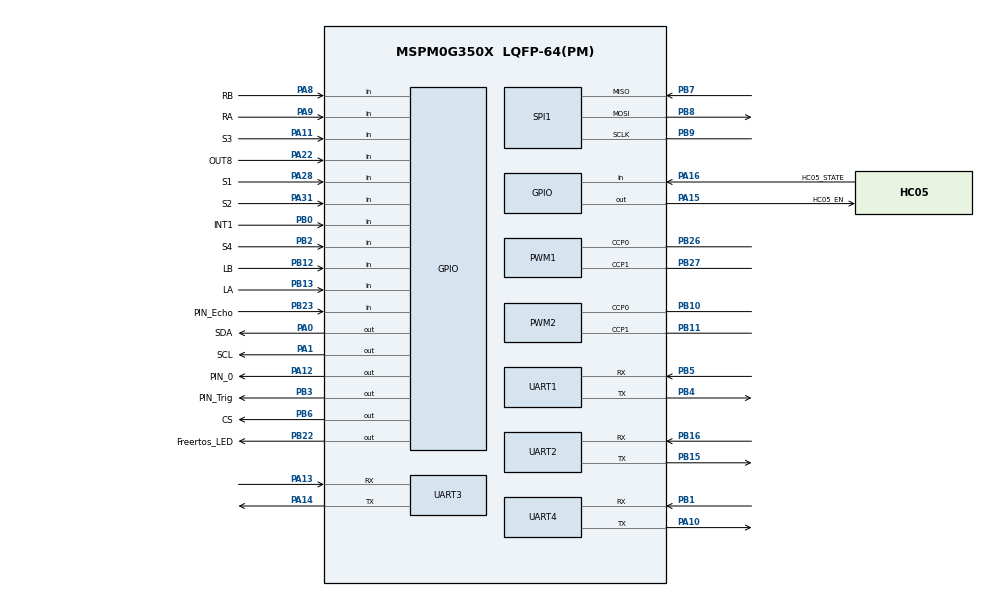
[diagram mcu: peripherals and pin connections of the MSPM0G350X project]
/**
 * @cliArgs --device "MSPM0G350X" --part "Default" --package "LQFP-64(PM)" --product "mspm0_sdk@2.10.00.04"
 * @versions {"tool":"1.27.0+4565"}
 */

/**
 * Import the modules used in this configuration.
 */
const GPIO   = scripting.addModule("/ti/driverlib/GPIO", {}, false);
const GPIO1  = GPIO.addInstance();
const GPIO2  = GPIO.addInstance();
const GPIO3  = GPIO.addInstance();
const GPIO4  = GPIO.addInstance();
const GPIO5  = GPIO.addInstance();
const GPIO6  = GPIO.addInstance();
const GPIO7  = GPIO.addInstance();
const GPIO8  = GPIO.addInstance();
const GPIO9  = GPIO.addInstance();
const GPIO10 = GPIO.addInstance();
const PWM    = scripting.addModule("/ti/driverlib/PWM", {}, false);
const PWM1   = PWM.addInstance();
const PWM2   = PWM.addInstance();
const SPI    = scripting.addModule("/ti/driverlib/SPI", {}, false);
const SPI1   = SPI.addInstance();
const SYSCTL = scripting.addModule("/ti/driverlib/SYSCTL");
const TIMER  = scripting.addModule("/ti/driverlib/TIMER", {}, false);
const TIMER1 = TIMER.addInstance();
const TIMER2 = TIMER.addInstance();
const TIMER3 = TIMER.addInstance();
const UART   = scripting.addModule("/ti/driverlib/UART", {}, false);
const UART1  = UART.addInstance();
const UART2  = UART.addInstance();
const UART3  = UART.addInstance();
const UART4  = UART.addInstance();

/**
 * Write custom configuration values to the imported modules.
 */
const divider7       = system.clockTree["PLL_PDIV"];
divider7.divideValue = 4;

const divider9       = system.clockTree["UDIV"];
divider9.divideValue = 2;

const multiplier2         = system.clockTree["PLL_QDIV"];
multiplier2.multiplyValue = 10;

const mux8       = system.clockTree["HSCLKMUX"];
mux8.inputSelect = "HSCLKMUX_SYSPLL2X";

GPIO1.$name                               = "GPIO_IMU";
GPIO1.associatedPins.create(2);
GPIO1.associatedPins[0].$name             = "CS";
GPIO1.associatedPins[0].initialValue      = "SET";
GPIO1.associatedPins[0].pin.$assign       = "PB6";
GPIO1.associatedPins[1].$name             = "INT1";
GPIO1.associatedPins[1].direction         = "INPUT";
GPIO1.associatedPins[1].polarity          = "RISE";
GPIO1.associatedPins[1].interruptPriority = "3";
GPIO1.associatedPins[1].interruptEn       = true;
GPIO1.associatedPins[1].internalResistor  = "PULL_DOWN";
GPIO1.associatedPins[1].pin.$assign       = "PB0";

const Board = scripting.addModule("/ti/driverlib/Board", {}, false);

GPIO2.$name                              = "ENCODER_A";
GPIO2.associatedPins.create(2);
GPIO2.associatedPins[0].$name            = "LA";
GPIO2.associatedPins[0].direction        = "INPUT";
GPIO2.associatedPins[0].internalResistor = "PULL_UP";
GPIO2.associatedPins[0].interruptEn      = true;
GPIO2.associatedPins[0].polarity         = "RISE";
GPIO2.associatedPins[0].pin.$assign      = "PB13";
GPIO2.associatedPins[1].$name            = "RA";
GPIO2.associatedPins[1].direction        = "INPUT";
GPIO2.associatedPins[1].internalResistor = "PULL_UP";
GPIO2.associatedPins[1].interruptEn      = true;
GPIO2.associatedPins[1].polarity         = "RISE";
GPIO2.associatedPins[1].pin.$assign      = "PA9";

GPIO3.$name                              = "ENCODER_B";
GPIO3.associatedPins.create(2);
GPIO3.associatedPins[0].$name            = "LB";
GPIO3.associatedPins[0].direction        = "INPUT";
GPIO3.associatedPins[0].internalResistor = "PULL_UP";
GPIO3.associatedPins[0].pin.$assign      = "PB12";
GPIO3.associatedPins[1].$name            = "RB";
GPIO3.associatedPins[1].direction        = "INPUT";
GPIO3.associatedPins[1].internalResistor = "PULL_UP";
GPIO3.associatedPins[1].pin.$assign      = "PA8";

GPIO4.$name                              = "GPIO_KEY";
GPIO4.associatedPins.create(4);
GPIO4.associatedPins[0].$name            = "S4";
GPIO4.associatedPins[0].direction        = "INPUT";
GPIO4.associatedPins[0].internalResistor = "PULL_UP";
GPIO4.associatedPins[0].pin.$assign      = "PB2";
GPIO4.associatedPins[1].$name            = "S3";
GPIO4.associatedPins[1].direction        = "INPUT";
GPIO4.associatedPins[1].assignedPort     = "PORTA";
GPIO4.associatedPins[1].internalResistor = "PULL_UP";
GPIO4.associatedPins[1].pin.$assign      = "PA11";
GPIO4.associatedPins[2].$name            = "S2";
GPIO4.associatedPins[2].direction        = "INPUT";
GPIO4.associatedPins[2].internalResistor = "PULL_UP";
GPIO4.associatedPins[2].pin.$assign      = "PA31";
GPIO4.associatedPins[3].$name            = "S1";
GPIO4.associatedPins[3].direction        = "INPUT";
GPIO4.associatedPins[3].internalResistor = "PULL_UP";
GPIO4.associatedPins[3].pin.$assign      = "PA28";

GPIO5.$name                              = "GPIO_Ultrasonic";
GPIO5.associatedPins.create(2);
GPIO5.associatedPins[0].$name            = "PIN_Trig";
GPIO5.associatedPins[0].pin.$assign      = "PB3";
GPIO5.associatedPins[1].$name            = "PIN_Echo";
GPIO5.associatedPins[1].direction        = "INPUT";
GPIO5.associatedPins[1].interruptEn      = true;
GPIO5.associatedPins[1].polarity         = "RISE_FALL";
GPIO5.associatedPins[1].internalResistor = "PULL_DOWN";
GPIO5.associatedPins[1].pin.$assign      = "PB23";

GPIO6.$name                          = "GPIO_GRAY";
GPIO6.associatedPins.create(8);
GPIO6.associatedPins[0].$name        = "OUT1";
GPIO6.associatedPins[0].direction    = "INPUT";
GPIO6.associatedPins[0].assignedPort = "PORTA";
GPIO6.associatedPins[0].assignedPin  = "27";
GPIO6.associatedPins[1].$name        = "OUT2";
GPIO6.associatedPins[1].direction    = "INPUT";
GPIO6.associatedPins[1].assignedPort = "PORTA";
GPIO6.associatedPins[1].assignedPin  = "26";
GPIO6.associatedPins[2].$name        = "OUT3";
GPIO6.associatedPins[2].direction    = "INPUT";
GPIO6.associatedPins[2].assignedPort = "PORTA";
GPIO6.associatedPins[2].assignedPin  = "25";
GPIO6.associatedPins[3].$name        = "OUT4";
GPIO6.associatedPins[3].direction    = "INPUT";
GPIO6.associatedPins[3].assignedPort = "PORTA";
GPIO6.associatedPins[3].assignedPin  = "24";
GPIO6.associatedPins[4].$name        = "OUT5";
GPIO6.associatedPins[4].direction    = "INPUT";
GPIO6.associatedPins[4].assignedPort = "PORTB";
GPIO6.associatedPins[4].assignedPin  = "25";
GPIO6.associatedPins[5].$name        = "OUT6";
GPIO6.associatedPins[5].direction    = "INPUT";
GPIO6.associatedPins[5].assignedPort = "PORTB";
GPIO6.associatedPins[5].assignedPin  = "24";
GPIO6.associatedPins[6].$name        = "OUT7";
GPIO6.associatedPins[6].direction    = "INPUT";
GPIO6.associatedPins[6].assignedPort = "PORTB";
GPIO6.associatedPins[6].assignedPin  = "20";
GPIO6.associatedPins[7].$name        = "OUT8";
GPIO6.associatedPins[7].direction    = "INPUT";
GPIO6.associatedPins[7].assignedPort = "PORTA";
GPIO6.associatedPins[7].assignedPin  = "22";
GPIO6.associatedPins[7].pin.$assign  = "PA22";

GPIO7.$name                          = "GPIO_OLED";
GPIO7.associatedPins.create(2);
GPIO7.associatedPins[0].$name        = "SDA";
GPIO7.associatedPins[0].initialValue = "SET";
GPIO7.associatedPins[0].assignedPort = "PORTA";
GPIO7.associatedPins[0].assignedPin  = "0";
GPIO7.associatedPins[0].ioStructure  = "OD";
GPIO7.associatedPins[0].pin.$assign  = "PA0";
GPIO7.associatedPins[1].$name        = "SCL";
GPIO7.associatedPins[1].initialValue = "SET";
GPIO7.associatedPins[1].assignedPort = "PORTA";
GPIO7.associatedPins[1].assignedPin  = "1";
GPIO7.associatedPins[1].ioStructure  = "OD";
GPIO7.associatedPins[1].pin.$assign  = "PA1";

GPIO8.$name                         = "GPIO_HC05";
GPIO8.associatedPins.create(2);
GPIO8.associatedPins[0].$name       = "HC05_EN";
GPIO8.associatedPins[0].pin.$assign = "PA15";
GPIO8.associatedPins[1].$name       = "HC05_STATE";
GPIO8.associatedPins[1].direction   = "INPUT";
GPIO8.associatedPins[1].pin.$assign = "PA16";

GPIO9.$name                         = "GPIO_LED";
GPIO9.associatedPins[0].$name       = "Freertos_LED";
GPIO9.associatedPins[0].pin.$assign = "PB22";

GPIO10.$name                          = "GPIO_BEEP";
GPIO10.associatedPins[0].$name        = "PIN_0";
GPIO10.associatedPins[0].initialValue = "SET";
GPIO10.associatedPins[0].pin.$assign  = "PA12";

PWM1.timerStartTimer                    = true;
PWM1.$name                              = "PWM_motor_L";
PWM1.timerCount                         = 7999;
PWM1.peripheral.$assign                 = "TIMG6";
PWM1.peripheral.ccp0Pin.$assign         = "PB26";
PWM1.peripheral.ccp1Pin.$assign         = "PB27";
PWM1.PWM_CHANNEL_0.$name                = "ti_driverlib_pwm_PWMTimerCC0";
PWM1.PWM_CHANNEL_1.$name                = "ti_driverlib_pwm_PWMTimerCC1";
PWM1.ccp0PinConfig.direction            = scripting.forceWrite("OUTPUT");
PWM1.ccp0PinConfig.hideOutputInversion  = scripting.forceWrite(false);
PWM1.ccp0PinConfig.onlyInternalResistor = scripting.forceWrite(false);
PWM1.ccp0PinConfig.passedPeripheralType = scripting.forceWrite("Digital");
PWM1.ccp0PinConfig.$name                = "ti_driverlib_gpio_GPIOPinGeneric3";
PWM1.ccp0PinConfig.enableConfig         = true;
PWM1.ccp0PinConfig.internalResistor     = "PULL_DOWN";
PWM1.ccp1PinConfig.direction            = scripting.forceWrite("OUTPUT");
PWM1.ccp1PinConfig.hideOutputInversion  = scripting.forceWrite(false);
PWM1.ccp1PinConfig.onlyInternalResistor = scripting.forceWrite(false);
PWM1.ccp1PinConfig.passedPeripheralType = scripting.forceWrite("Digital");
PWM1.ccp1PinConfig.$name                = "ti_driverlib_gpio_GPIOPinGeneric4";
PWM1.ccp1PinConfig.enableConfig         = true;
PWM1.ccp1PinConfig.internalResistor     = "PULL_DOWN";

PWM2.$name                              = "PWM_motor_R";
PWM2.timerStartTimer                    = true;
PWM2.timerCount                         = 3999;
PWM2.peripheral.$assign                 = "TIMG8";
PWM2.peripheral.ccp0Pin.$assign         = "PB10";
PWM2.peripheral.ccp1Pin.$assign         = "PB11";
PWM2.PWM_CHANNEL_0.$name                = "ti_driverlib_pwm_PWMTimerCC2";
PWM2.PWM_CHANNEL_1.$name                = "ti_driverlib_pwm_PWMTimerCC3";
PWM2.ccp0PinConfig.direction            = scripting.forceWrite("OUTPUT");
PWM2.ccp0PinConfig.hideOutputInversion  = scripting.forceWrite(false);
PWM2.ccp0PinConfig.onlyInternalResistor = scripting.forceWrite(false);
PWM2.ccp0PinConfig.passedPeripheralType = scripting.forceWrite("Digital");
PWM2.ccp0PinConfig.$name                = "ti_driverlib_gpio_GPIOPinGeneric5";
PWM2.ccp0PinConfig.enableConfig         = true;
PWM2.ccp0PinConfig.internalResistor     = "PULL_DOWN";
PWM2.ccp1PinConfig.direction            = scripting.forceWrite("OUTPUT");
PWM2.ccp1PinConfig.hideOutputInversion  = scripting.forceWrite(false);
PWM2.ccp1PinConfig.onlyInternalResistor = scripting.forceWrite(false);
PWM2.ccp1PinConfig.passedPeripheralType = scripting.forceWrite("Digital");
PWM2.ccp1PinConfig.$name                = "ti_driverlib_gpio_GPIOPinGeneric6";
PWM2.ccp1PinConfig.enableConfig         = true;
PWM2.ccp1PinConfig.internalResistor     = "PULL_DOWN";

SPI1.$name                      = "SPI_0";
SPI1.frameFormat                = "MOTO3";
SPI1.targetBitRate              = 4000000;
SPI1.polarity                   = "1";
SPI1.phase                      = "1";
SPI1.sclkPinConfig.$name        = "ti_driverlib_gpio_GPIOPinGeneric0";
SPI1.mosiPinConfig.$name        = "ti_driverlib_gpio_GPIOPinGeneric1";
SPI1.misoPinConfig.$name        = "ti_driverlib_gpio_GPIOPinGeneric2";
SPI1.peripheral.$assign         = "SPI1";
SPI1.peripheral.sclkPin.$assign = "PB9";
SPI1.peripheral.mosiPin.$assign = "PB8";
SPI1.peripheral.misoPin.$assign = "PB7";

SYSCTL.clockTreeEn = true;

TIMER1.$name              = "TIMER_STATS";
TIMER1.timerMode          = "PERIODIC_UP";
TIMER1.timerStartTimer    = true;
TIMER1.timerClkDiv        = 8;
TIMER1.timerPeriod        = "107374 ms";
TIMER1.peripheral.$assign = "TIMG12";

TIMER2.$name            = "TIMER_Ultrasonic";
TIMER2.timerClkPrescale = 32;
TIMER2.timerMode        = "ONE_SHOT_UP";
TIMER2.timerPeriod      = "25ms";

TIMER3.$name              = "IMU_dt";
TIMER3.timerMode          = "PERIODIC_UP";
TIMER3.timerClkDiv        = 8;
TIMER3.timerPeriod        = "1000ms";
TIMER3.timerClkPrescale   = 200;
TIMER3.peripheral.$assign = "TIMG7";

UART1.targetBaudRate                   = 115200;
UART1.enabledInterrupts                = ["RX"];
UART1.$name                            = "UART_1";
UART1.peripheral.$assign               = "UART1";
UART1.peripheral.rxPin.$assign         = "PB5";
UART1.peripheral.txPin.$assign         = "PB4";
UART1.txPinConfig.direction            = scripting.forceWrite("OUTPUT");
UART1.txPinConfig.hideOutputInversion  = scripting.forceWrite(false);
UART1.txPinConfig.onlyInternalResistor = scripting.forceWrite(false);
UART1.txPinConfig.passedPeripheralType = scripting.forceWrite("Digital");
UART1.txPinConfig.$name                = "ti_driverlib_gpio_GPIOPinGeneric7";
UART1.rxPinConfig.hideOutputInversion  = scripting.forceWrite(false);
UART1.rxPinConfig.onlyInternalResistor = scripting.forceWrite(false);
UART1.rxPinConfig.passedPeripheralType = scripting.forceWrite("Digital");
UART1.rxPinConfig.$name                = "ti_driverlib_gpio_GPIOPinGeneric8";

UART2.targetBaudRate                   = 115200;
UART2.enabledInterrupts                = ["RX"];
UART2.$name                            = "UART_2";
UART2.peripheral.$assign               = "UART2";
UART2.peripheral.rxPin.$assign         = "PB16";
UART2.peripheral.txPin.$assign         = "PB15";
UART2.txPinConfig.direction            = scripting.forceWrite("OUTPUT");
UART2.txPinConfig.hideOutputInversion  = scripting.forceWrite(false);
UART2.txPinConfig.onlyInternalResistor = scripting.forceWrite(false);
UART2.txPinConfig.passedPeripheralType = scripting.forceWrite("Digital");
UART2.txPinConfig.$name                = "ti_driverlib_gpio_GPIOPinGeneric9";
UART2.rxPinConfig.hideOutputInversion  = scripting.forceWrite(false);
UART2.rxPinConfig.onlyInternalResistor = scripting.forceWrite(false);
UART2.rxPinConfig.passedPeripheralType = scripting.forceWrite("Digital");
UART2.rxPinConfig.$name                = "ti_driverlib_gpio_GPIOPinGeneric10";

UART3.enabledInterrupts                = ["RX"];
UART3.$name                            = "UART_3";
UART3.targetBaudRate                   = 115200;
UART3.peripheral.$assign               = "UART3";
UART3.peripheral.rxPin.$assign         = "PA13";
UART3.peripheral.txPin.$assign         = "PA14";
UART3.txPinConfig.direction            = scripting.forceWrite("OUTPUT");
UART3.txPinConfig.hideOutputInversion  = scripting.forceWrite(false);
UART3.txPinConfig.onlyInternalResistor = scripting.forceWrite(false);
UART3.txPinConfig.passedPeripheralType = scripting.forceWrite("Digital");
UART3.txPinConfig.$name                = "ti_driverlib_gpio_GPIOPinGeneric11";
UART3.rxPinConfig.hideOutputInversion  = scripting.forceWrite(false);
UART3.rxPinConfig.onlyInternalResistor = scripting.forceWrite(false);
UART3.rxPinConfig.passedPeripheralType = scripting.forceWrite("Digital");
UART3.rxPinConfig.$name                = "ti_driverlib_gpio_GPIOPinGeneric12";

UART4.targetBaudRate                   = 115200;
UART4.enabledInterrupts                = ["RX"];
UART4.$name                            = "UART_ZDT";
UART4.peripheral.$assign               = "UART0";
UART4.peripheral.rxPin.$assign         = "PB1";
UART4.peripheral.txPin.$assign         = "PA10";
UART4.txPinConfig.direction            = scripting.forceWrite("OUTPUT");
UART4.txPinConfig.hideOutputInversion  = scripting.forceWrite(false);
UART4.txPinConfig.onlyInternalResistor = scripting.forceWrite(false);
UART4.txPinConfig.passedPeripheralType = scripting.forceWrite("Digital");
UART4.txPinConfig.$name                = "ti_driverlib_gpio_GPIOPinGeneric13";
UART4.rxPinConfig.hideOutputInversion  = scripting.forceWrite(false);
UART4.rxPinConfig.onlyInternalResistor = scripting.forceWrite(false);
UART4.rxPinConfig.passedPeripheralType = scripting.forceWrite("Digital");
UART4.rxPinConfig.$name                = "ti_driverlib_gpio_GPIOPinGeneric14";

/**
 * Pinmux solution for unlocked pins/peripherals. This ensures that minor changes to the automatic solver in a future
 * version of the tool will not impact the pinmux you originally saw.  These lines can be completely deleted in order to
 * re-solve from scratch.
 */
Board.peripheral.$suggestSolution            = "DEBUGSS";
Board.peripheral.swclkPin.$suggestSolution   = "PA20";
Board.peripheral.swdioPin.$suggestSolution   = "PA19";
GPIO6.associatedPins[0].pin.$suggestSolution = "PA27";
GPIO6.associatedPins[1].pin.$suggestSolution = "PA26";
GPIO6.associatedPins[2].pin.$suggestSolution = "PA25";
GPIO6.associatedPins[3].pin.$suggestSolution = "PA24";
GPIO6.associatedPins[4].pin.$suggestSolution = "PB25";
GPIO6.associatedPins[5].pin.$suggestSolution = "PB24";
GPIO6.associatedPins[6].pin.$suggestSolution = "PB20";
TIMER2.peripheral.$suggestSolution           = "TIMA0";
